# CY8C5888LTI_LP097 register map
File version: 0.1
CY8C58LP
Registers are 8-bit, read-write, no defined reset value unless marked. A register's access mark holds for its fields unless they carry their own. Offsets are from the block's base; lines under a group give offsets from that group; [hi:lo] are bit positions; {n}, {i} and the like mark numbered series; 'fields as' and 'values as' point back to an identical list; <NAME> marks a mode.

## Memory map
0x00000000 Timeout_3
0x00000000 Timeout_5
0x00000000 Timeout_4
0x00000000 Timeout_1
0x00000000 Timeout_2
0x00000000 QuadDec_1
0x00000000 QuadDec_1_Cnt16
0x00000000 PWM_2
0x00000000 PWM_1
0x00000000 VDAC8_1

## Timeout_3
Base 0x00000000
0x4000640C Timeout_3_COUNTER 16-bit — UDB.A0 - Current Down Counter Value
0x4000642C Timeout_3_PERIOD 16-bit — UDB.D0 - Assigned Period
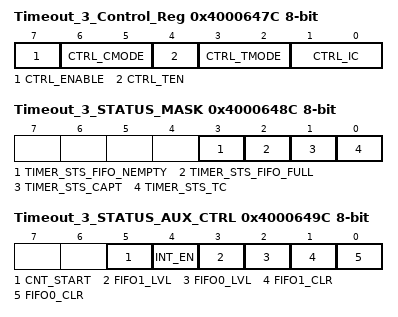
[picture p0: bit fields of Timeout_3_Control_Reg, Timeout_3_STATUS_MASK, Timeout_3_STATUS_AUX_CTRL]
0x4000647C Timeout_3_Control_Reg — UDB Control Register - Assigned Control Register Value
  [7] CTRL_ENABLE — Enable the Timer
  [6:5] CTRL_CMODE — Capture Mode
  [4] CTRL_TEN — Trigger Enable Bit
  [3:2] CTRL_TMODE — Trigger Mode
  [1:0] CTRL_IC — Interrupt Count
0x4000648C Timeout_3_STATUS_MASK — UDB Status bits Interrupt Mask Enable Register
  [3] TIMER_STS_FIFO_NEMPTY ro — FIFO Empty status
  [2] TIMER_STS_FIFO_FULL ro — FIFO Full Status
  [1] TIMER_STS_CAPT ro — Enables the Interrupt on Capture
  [0] TIMER_STS_TC ro — Enables the Interrupt on TC
0x4000649C Timeout_3_STATUS_AUX_CTRL — UDB Auxilliary Control Register
  [5] CNT_START — FIFO0 clear
    0=E_CNT_START0 (Disable counter); 1=E_CNT_START1 (Enable counter)
  [4] INT_EN
    0=E_INT_EN0 (Interrupt disabled); 1=E_INT_EN1 (Interrupt enabled)
  [3] FIFO1_LVL — FIFO level
    0=E_FIFO_LVL_0 (FIFO LVL: input mode: FIFO not full; output mode: FIFO not empty); 1=E_FIFO_LVL_1 (FIFO LVL: input mode: FIFO at least 1/2 empty; output mode: FIFO at least 1/2 full)
  [2] FIFO0_LVL — FIFO level
    values as FIFO1_LVL
  [1] FIFO1_CLR — FIFO1 clear
    0=E_FIFO_CLR_0 (Normal FIFO operation); 1=E_FIFO_CLR_1 (Clear FIFO state)
  [0] FIFO0_CLR — FIFO0 clear
    values as FIFO1_CLR

## Timeout_5
Base 0x00000000
0x40006406 Timeout_5_COUNTER 16-bit — UDB.A0 - Current Down Counter Value
0x40006426 Timeout_5_PERIOD 16-bit — UDB.D0 - Assigned Period
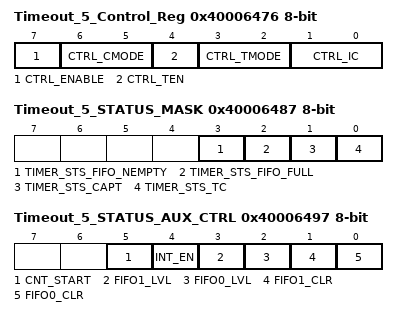
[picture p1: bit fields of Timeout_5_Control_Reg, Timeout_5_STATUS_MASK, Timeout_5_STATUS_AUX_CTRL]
0x40006476 Timeout_5_Control_Reg — UDB Control Register - Assigned Control Register Value
  [7] CTRL_ENABLE — Enable the Timer
  [6:5] CTRL_CMODE — Capture Mode
  [4] CTRL_TEN — Trigger Enable Bit
  [3:2] CTRL_TMODE — Trigger Mode
  [1:0] CTRL_IC — Interrupt Count
0x40006487 Timeout_5_STATUS_MASK — UDB Status bits Interrupt Mask Enable Register
  [3] TIMER_STS_FIFO_NEMPTY ro — FIFO Empty status
  [2] TIMER_STS_FIFO_FULL ro — FIFO Full Status
  [1] TIMER_STS_CAPT ro — Enables the Interrupt on Capture
  [0] TIMER_STS_TC ro — Enables the Interrupt on TC
0x40006497 Timeout_5_STATUS_AUX_CTRL — UDB Auxilliary Control Register
  [5] CNT_START — FIFO0 clear
    0=E_CNT_START0 (Disable counter); 1=E_CNT_START1 (Enable counter)
  [4] INT_EN
    0=E_INT_EN0 (Interrupt disabled); 1=E_INT_EN1 (Interrupt enabled)
  [3] FIFO1_LVL — FIFO level
    0=E_FIFO_LVL_0 (FIFO LVL: input mode: FIFO not full; output mode: FIFO not empty); 1=E_FIFO_LVL_1 (FIFO LVL: input mode: FIFO at least 1/2 empty; output mode: FIFO at least 1/2 full)
  [2] FIFO0_LVL — FIFO level
    values as FIFO1_LVL
  [1] FIFO1_CLR — FIFO1 clear
    0=E_FIFO_CLR_0 (Normal FIFO operation); 1=E_FIFO_CLR_1 (Clear FIFO state)
  [0] FIFO0_CLR — FIFO0 clear
    values as FIFO1_CLR

## Timeout_4
Base 0x00000000
0x40006408 Timeout_4_COUNTER 16-bit — UDB.A0 - Current Down Counter Value
0x40006428 Timeout_4_PERIOD 16-bit — UDB.D0 - Assigned Period
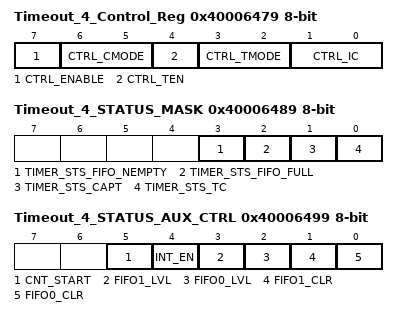
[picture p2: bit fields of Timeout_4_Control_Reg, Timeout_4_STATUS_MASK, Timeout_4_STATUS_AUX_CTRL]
0x40006479 Timeout_4_Control_Reg — UDB Control Register - Assigned Control Register Value
  [7] CTRL_ENABLE — Enable the Timer
  [6:5] CTRL_CMODE — Capture Mode
  [4] CTRL_TEN — Trigger Enable Bit
  [3:2] CTRL_TMODE — Trigger Mode
  [1:0] CTRL_IC — Interrupt Count
0x40006489 Timeout_4_STATUS_MASK — UDB Status bits Interrupt Mask Enable Register
  [3] TIMER_STS_FIFO_NEMPTY ro — FIFO Empty status
  [2] TIMER_STS_FIFO_FULL ro — FIFO Full Status
  [1] TIMER_STS_CAPT ro — Enables the Interrupt on Capture
  [0] TIMER_STS_TC ro — Enables the Interrupt on TC
0x40006499 Timeout_4_STATUS_AUX_CTRL — UDB Auxilliary Control Register
  [5] CNT_START — FIFO0 clear
    0=E_CNT_START0 (Disable counter); 1=E_CNT_START1 (Enable counter)
  [4] INT_EN
    0=E_INT_EN0 (Interrupt disabled); 1=E_INT_EN1 (Interrupt enabled)
  [3] FIFO1_LVL — FIFO level
    0=E_FIFO_LVL_0 (FIFO LVL: input mode: FIFO not full; output mode: FIFO not empty); 1=E_FIFO_LVL_1 (FIFO LVL: input mode: FIFO at least 1/2 empty; output mode: FIFO at least 1/2 full)
  [2] FIFO0_LVL — FIFO level
    values as FIFO1_LVL
  [1] FIFO1_CLR — FIFO1 clear
    0=E_FIFO_CLR_0 (Normal FIFO operation); 1=E_FIFO_CLR_1 (Clear FIFO state)
  [0] FIFO0_CLR — FIFO0 clear
    values as FIFO1_CLR
